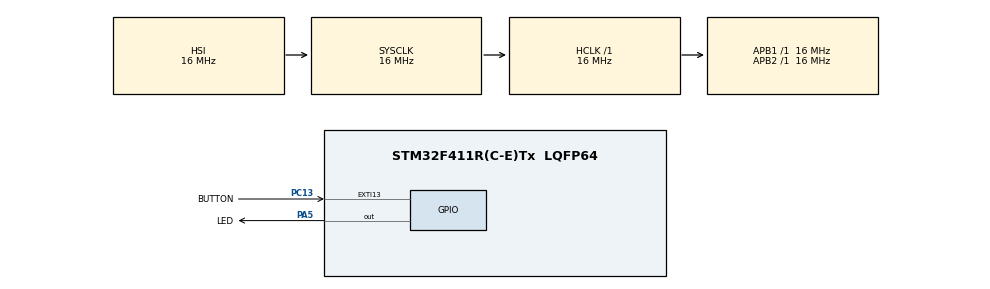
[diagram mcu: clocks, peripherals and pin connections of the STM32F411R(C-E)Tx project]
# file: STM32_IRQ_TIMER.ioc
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Mcu.Family=STM32F4
Mcu.Name=STM32F411R(C-E)Tx
Mcu.Package=LQFP64
NVIC.EXTI15_10_IRQn=true\:0\:0\:true\:false\:true\:true\:true\:true
NVIC.PriorityGroup=NVIC_PRIORITYGROUP_4
NVIC.TIM2_IRQn=true\:0\:0\:false\:false\:true\:true\:true\:true
PA5.GPIO_Label=LED
PA5.Signal=GPIO_Output
PC13-ANTI_TAMP.GPIO_Label=BUTTON
PC13-ANTI_TAMP.GPIO_ModeDefaultEXTI=GPIO_MODE_IT_FALLING
PC13-ANTI_TAMP.GPIO_PuPd=GPIO_PULLUP
PC13-ANTI_TAMP.Signal=GPXTI13
ProjectManager.HeapSize=0x200
ProjectManager.StackSize=0x400
ProjectManager.TargetToolchain=STM32CubeIDE
RCC.AHBFreq_Value=16000000
RCC.APB1Freq_Value=16000000
RCC.APB2Freq_Value=16000000
RCC.CortexFreq_Value=16000000
RCC.HSE_VALUE=25000000
RCC.HSI_VALUE=16000000
RCC.LSE_VALUE=32768
RCC.SYSCLKFreq_VALUE=16000000
RCC.VCOOutputFreq_Value=192000000
TIM2.AutoReloadPreload=TIM_AUTORELOAD_PRELOAD_ENABLE
TIM2.Period=500-1
TIM2.Prescaler=16000-1
VP_TIM2_VS_ClockSourceINT.Mode=Internal
board=custom

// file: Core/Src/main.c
/* USER CODE BEGIN Header */
/**
  ******************************************************************************
  * @file           : main.c
  * @brief          : Main program body
  ******************************************************************************
  * @attention
  *
  * Copyright (c) 2026 STMicroelectronics.
  * All rights reserved.
  *
  * This software is licensed under terms that can be found in the LICENSE file
  * in the root directory of this software component.
  * If no LICENSE file comes with this software, it is provided AS-IS.
  *
  ******************************************************************************
  */
/* USER CODE END Header */
#include "main.h"
#include "tim.h"
#include "gpio.h"

/* USER CODE BEGIN PV */
typedef enum {
    LED_BLINK_OFF = 0,
    LED_BLINK_ON = 1
} led_blink_state_t;

typedef enum {
    LED_OFF = 0,
    LED_ON = 1
} led_state_t;

led_blink_state_t led_blink_state = LED_BLINK_OFF;
led_state_t led_state = LED_OFF;
/* USER CODE END PV */

void SystemClock_Config(void);

/* USER CODE BEGIN 0 */
/**
  * @brief  EXTI line detection callbacks.
  * @param  GPIO_Pin Specifies the pins connected EXTI line
  * @retval None
  */
void HAL_GPIO_EXTI_Callback(uint16_t GPIO_Pin)
{
  if (led_blink_state == LED_BLINK_OFF)
  {
    led_blink_state = LED_BLINK_ON;
    HAL_TIM_Base_Start_IT(&htim2);
  }
  else
  {
    led_blink_state = LED_BLINK_OFF;
    HAL_TIM_Base_Stop_IT(&htim2);
    __HAL_TIM_SET_COUNTER(&htim2, 0);   // Reset counter to 0
  }
}
void HAL_TIM_PeriodElapsedCallback(TIM_HandleTypeDef *htim)
{
  if (led_state == LED_OFF)
  {
    led_state = LED_ON;
  }
  else
  {
    led_state = LED_OFF;
  }
}
/* USER CODE END 0 */

int main(void)
{

  /* MCU Configuration--------------------------------------------------------*/

  /* Reset of all peripherals, Initializes the Flash interface and the Systick. */
  HAL_Init();

  /* Configure the system clock */
  SystemClock_Config();

  /* Initialize all configured peripherals */
  MX_GPIO_Init();
  MX_TIM2_Init();

  /* Infinite loop */
  /* USER CODE BEGIN WHILE */
  while (1)
  {
    if (led_blink_state == LED_BLINK_ON)
    {
      if (led_state == LED_OFF)
      {
        HAL_GPIO_WritePin(LED_GPIO_Port, LED_Pin, GPIO_PIN_RESET); // Turn off LED
      }
      else
      {
        HAL_GPIO_WritePin(LED_GPIO_Port, LED_Pin, GPIO_PIN_SET); // Turn on LED
      }
    }
    else
    {
      led_state = LED_OFF;
      HAL_GPIO_WritePin(LED_GPIO_Port, LED_Pin, GPIO_PIN_RESET); // Ensure LED is off
    }

    /* USER CODE END WHILE */

  }
}

void SystemClock_Config(void)
{
  RCC_OscInitTypeDef RCC_OscInitStruct = {0};
  RCC_ClkInitTypeDef RCC_ClkInitStruct = {0};

  /** Configure the main internal regulator output voltage
  */
  __HAL_RCC_PWR_CLK_ENABLE();
  __HAL_PWR_VOLTAGESCALING_CONFIG(PWR_REGULATOR_VOLTAGE_SCALE1);

  /** Initializes the RCC Oscillators according to the specified parameters
  * in the RCC_OscInitTypeDef structure.
  */
  RCC_OscInitStruct.OscillatorType = RCC_OSCILLATORTYPE_HSI;
  RCC_OscInitStruct.HSIState = RCC_HSI_ON;
  RCC_OscInitStruct.HSICalibrationValue = RCC_HSICALIBRATION_DEFAULT;
  RCC_OscInitStruct.PLL.PLLState = RCC_PLL_NONE;
  if (HAL_RCC_OscConfig(&RCC_OscInitStruct) != HAL_OK)
  {
    Error_Handler();
  }

  /** Initializes the CPU, AHB and APB buses clocks
  */
  RCC_ClkInitStruct.ClockType = RCC_CLOCKTYPE_HCLK|RCC_CLOCKTYPE_SYSCLK
                              |RCC_CLOCKTYPE_PCLK1|RCC_CLOCKTYPE_PCLK2;
  RCC_ClkInitStruct.SYSCLKSource = RCC_SYSCLKSOURCE_HSI;
  RCC_ClkInitStruct.AHBCLKDivider = RCC_SYSCLK_DIV1;
  RCC_ClkInitStruct.APB1CLKDivider = RCC_HCLK_DIV1;
  RCC_ClkInitStruct.APB2CLKDivider = RCC_HCLK_DIV1;

  if (HAL_RCC_ClockConfig(&RCC_ClkInitStruct, FLASH_LATENCY_0) != HAL_OK)
  {
    Error_Handler();
  }
}

void Error_Handler(void)
{
  __disable_irq();
  while (1)
  {
  }
}
